# MSP430FR5962 register map
File version: 2.1
CPU: MSP430FR5962 r2p1, little endian, MPU, no FPU, 3 interrupt priority bits
Registers are 16-bit, read-write, reset 0x0 unless marked. A register's access mark holds for its fields unless they carry their own. Offsets are from the block's base; [hi:lo] are bit positions; {n}, {i} and the like mark numbered series.

## CAPTIO0
Base 0x00000430
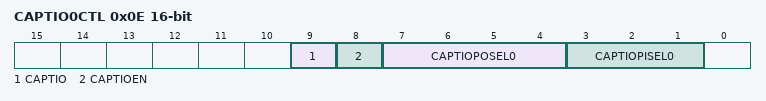
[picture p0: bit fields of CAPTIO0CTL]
0x0E CAPTIO0CTL — Capacitive Touch IO 0 Control Register
  [9] CAPTIO — [9:9] Capacitive Touch IO state
    0=Curent state 0 or Capacitive Touch IO is disabled; 1=Current state 1
  [8] CAPTIOEN — [8:8] Capacitive Touch IO enable
    0=OFF (All Capacitive Touch IOs are disabled. Signal towards timers is 0.); 1=ON (Selected Capacitive Touch IO is enabled)
  [7:4] CAPTIOPOSEL0 — [7:4] Capacitive Touch IO port select
    0=PJ (Px = PJ); {v}=P{v} (Px = P{v}) (v=1..15)
  [3:1] CAPTIOPISEL0 — [3:1] Capacitive Touch IO pin select
    0=CAPTIOPISEL_0 (Px.0); 1=CAPTIOPISEL_1 (Px.1); 2=CAPTIOPISEL_2 (Px.2); 3=CAPTIOPISEL_3 (Px.3); 4=CAPTIOPISEL_4 (Px.4); 5=CAPTIOPISEL_5 (Px.5); 6=CAPTIOPISEL_6 (Px.6); 7=CAPTIOPISEL_7 (Px.7)

## CAPTIO1
Base 0x00000470
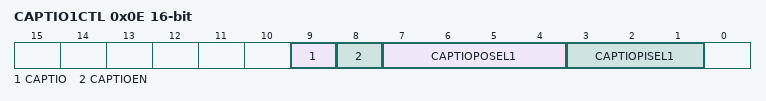
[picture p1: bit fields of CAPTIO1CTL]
0x0E CAPTIO1CTL — Capacitive Touch IO 0 Control Register
  [9] CAPTIO — [9:9] Capacitive Touch IO state
    0=Curent state 0 or Capacitive Touch IO is disabled; 1=Current state 1
  [8] CAPTIOEN — [8:8] Capacitive Touch IO enable
    0=OFF (All Capacitive Touch IOs are disabled. Signal towards timers is 0.); 1=ON (Selected Capacitive Touch IO is enabled)
  [7:4] CAPTIOPOSEL1 — [7:4] Capacitive Touch IO port select
    0=PJ (Px = PJ); {v}=P{v} (Px = P{v}) (v=1..15)
  [3:1] CAPTIOPISEL1 — [3:1] Capacitive Touch IO pin select
    0=CAPTIOPISEL_0 (Px.0); 1=CAPTIOPISEL_1 (Px.1); 2=CAPTIOPISEL_2 (Px.2); 3=CAPTIOPISEL_3 (Px.3); 4=CAPTIOPISEL_4 (Px.4); 5=CAPTIOPISEL_5 (Px.5); 6=CAPTIOPISEL_6 (Px.6); 7=CAPTIOPISEL_7 (Px.7)

## CRC
Base 0x00000150
0x00 CRCDI — CRC Data In
0x02 CRCDIRB — CRC Data In Reverse Byte
0x04 CRCINIRES — CRC Initialization and Result
0x06 CRCRESR — CRC Result Reverse

## CRC32
Base 0x00000980
0x00 CRC32DIW0 — CRC32 Data Input Word 0
0x02 CRC32DIW1 — CRC32 Data Input Word 1
0x04 CRC32DIRBW1 — CRC32 Data In Reverse Word 1
0x06 CRC32DIRBW0 — CRC32 Data In Reverse Word 0
0x08 CRC32INIRESW0 — CRC32 Initialization and Result Word 0
0x0A CRC32INIRESW1 — CRC32 Initialization and Result Word 1
0x0C CRC32RESRW1 — CRC32 Result Reverse Word 1
0x0E CRC32RESRW0 — CRC32 Result Reverse Word 0
0x10 CRC16DIW0 — CRC16 Data Input
0x16 CRC16DIRBW0 — CRC16 Data In Reverse
0x18 CRC16INIRESW0 — CRC16 Init and Result
0x1E CRC16RESRW0 — CRC16 Result Reverse

## PA
Base 0x00000200
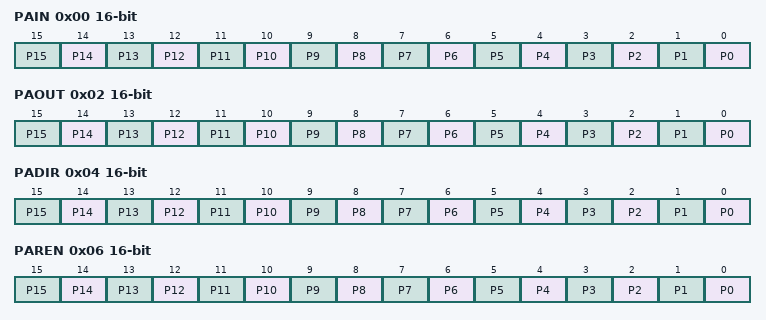
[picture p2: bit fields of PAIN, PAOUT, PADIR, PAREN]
0x00 PAIN — Port A Input
  [n] P{n} (n=0..15)
0x02 PAOUT — Port A Output
  [n] P{n} (n=0..15)
0x04 PADIR — Port A Direction
  [n] P{n} (n=0..15)
0x06 PAREN — Port A Resistor Enable
  [n] P{n} (n=0..15)
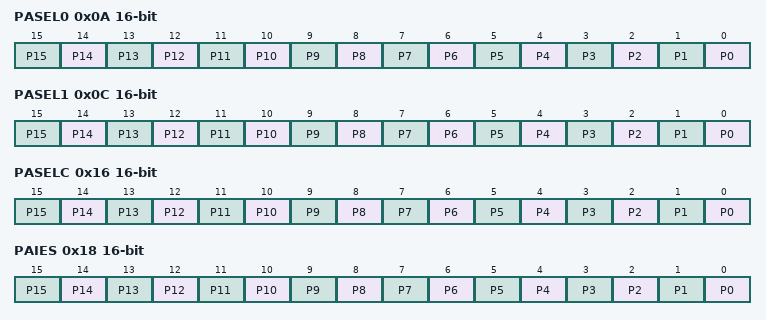
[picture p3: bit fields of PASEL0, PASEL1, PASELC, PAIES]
0x0A PASEL0 — Port A Select 0
  [n] P{n} (n=0..15)
0x0C PASEL1 — Port A Select 1
  [n] P{n} (n=0..15)
0x16 PASELC — Port A Complement Select
  [n] P{n} (n=0..15)
0x18 PAIES — Port A Interrupt Edge Select
  [n] P{n} (n=0..15)
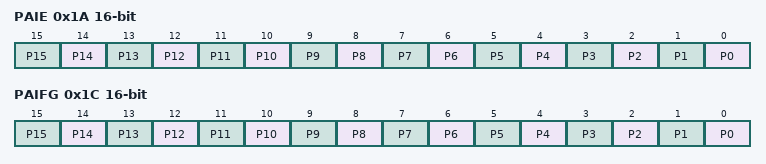
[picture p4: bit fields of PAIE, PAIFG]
0x1A PAIE — Port A Interrupt Enable
  [n] P{n} (n=0..15)
0x1C PAIFG — Port A Interrupt Flag
  [n] P{n} (n=0..15)

## P1
Base 0x00000200
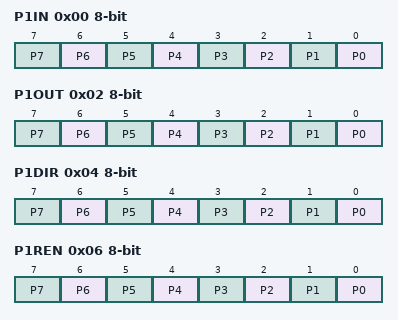
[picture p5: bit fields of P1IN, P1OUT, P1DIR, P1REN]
0x00 P1IN 8-bit — Port 1 Input
  [n] P{n} (n=0..7)
0x02 P1OUT 8-bit — Port 1 Output
  [n] P{n} (n=0..7)
0x04 P1DIR 8-bit — Port 1 Direction
  [n] P{n} (n=0..7)
0x06 P1REN 8-bit — Port 1 Resistor Enable
  [n] P{n} (n=0..7)
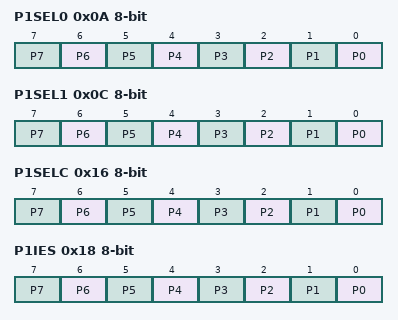
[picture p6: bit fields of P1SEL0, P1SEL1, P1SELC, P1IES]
0x0A P1SEL0 8-bit — Port 1 Select 0
  [n] P{n} (n=0..7)
0x0C P1SEL1 8-bit — Port 1 Select 1
  [n] P{n} (n=0..7)
0x0E P1IV — Port 1 Interrupt Vector Register
  [4:0] P1IV — [4:0] Port 1 interrupt vector value
    0=NONE (No interrupt pending); 2=P1IFG0 (Interrupt Source: Port 1.0 interrupt; Interrupt Flag: P1IFG0; Interrupt Priority: Highest); 4=P1IFG1 (Interrupt Source: Port 1.1 interrupt; Interrupt Flag: P1IFG1); 6=P1IFG2 (Interrupt Source: Port 1.2 interrupt; Interrupt Flag: P1IFG2); 8=P1IFG3 (Interrupt Source: Port 1.3 interrupt; Interrupt Flag: P1IFG3); 10=P1IFG4 (Interrupt Source: Port 1.4 interrupt; Interrupt Flag: P1IFG4); 12=P1IFG5 (Interrupt Source: Port 1.5 interrupt; Interrupt Flag: P1IFG5); 14=P1IFG6 (Interrupt Source: Port 1.6 interrupt; Interrupt Flag: P1IFG6); 16=P1IFG7 (Interrupt Source: Port 1.7 interrupt; Interrupt Flag: P1IFG7; Interrupt Priority: Lowest)
0x16 P1SELC 8-bit — Port 1 Complement Select
  [n] P{n} (n=0..7)
0x18 P1IES 8-bit — Port 1 Interrupt Edge Select
  [n] P{n} (n=0..7)
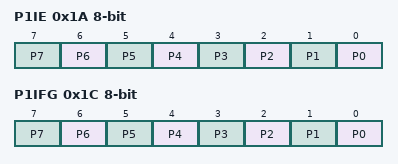
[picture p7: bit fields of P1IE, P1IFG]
0x1A P1IE 8-bit — Port 1 Interrupt Enable
  [n] P{n} (n=0..7)
0x1C P1IFG 8-bit — Port 1 Interrupt Flag
  [n] P{n} (n=0..7)
